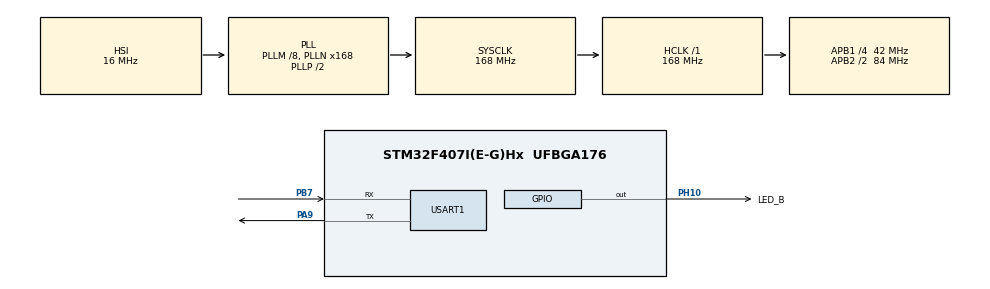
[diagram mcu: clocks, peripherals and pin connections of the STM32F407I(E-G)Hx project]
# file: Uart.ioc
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Dma.Request0=USART1_RX
Dma.Request1=USART1_TX
Dma.USART1_RX.0.Direction=DMA_PERIPH_TO_MEMORY
Dma.USART1_RX.0.FIFOMode=DMA_FIFOMODE_DISABLE
Dma.USART1_RX.0.Instance=DMA2_Stream2
Dma.USART1_RX.0.MemDataAlignment=DMA_MDATAALIGN_BYTE
Dma.USART1_RX.0.MemInc=DMA_MINC_ENABLE
Dma.USART1_RX.0.Mode=DMA_NORMAL
Dma.USART1_RX.0.PeriphDataAlignment=DMA_PDATAALIGN_BYTE
Dma.USART1_RX.0.PeriphInc=DMA_PINC_DISABLE
Dma.USART1_RX.0.Priority=DMA_PRIORITY_LOW
Dma.USART1_TX.1.Direction=DMA_MEMORY_TO_PERIPH
Dma.USART1_TX.1.FIFOMode=DMA_FIFOMODE_DISABLE
Dma.USART1_TX.1.Instance=DMA2_Stream7
Dma.USART1_TX.1.MemDataAlignment=DMA_MDATAALIGN_BYTE
Dma.USART1_TX.1.MemInc=DMA_MINC_ENABLE
Dma.USART1_TX.1.Mode=DMA_NORMAL
Dma.USART1_TX.1.PeriphDataAlignment=DMA_PDATAALIGN_BYTE
Dma.USART1_TX.1.PeriphInc=DMA_PINC_DISABLE
Dma.USART1_TX.1.Priority=DMA_PRIORITY_LOW
Mcu.Family=STM32F4
Mcu.Name=STM32F407I(E-G)Hx
Mcu.Package=UFBGA176
NVIC.DMA2_Stream2_IRQn=true\:0\:0\:false\:false\:true\:false\:true\:true
NVIC.DMA2_Stream7_IRQn=true\:0\:0\:false\:false\:true\:false\:true\:true
NVIC.PriorityGroup=NVIC_PRIORITYGROUP_4
NVIC.USART1_IRQn=true\:0\:0\:false\:false\:true\:true\:true\:true
PA9.Mode=Asynchronous
PA9.Signal=USART1_TX
PB7.Mode=Asynchronous
PB7.Signal=USART1_RX
PH0-OSC_IN.Mode=HSE-External-Oscillator
PH0-OSC_IN.Signal=RCC_OSC_IN
PH1-OSC_OUT.Mode=HSE-External-Oscillator
PH1-OSC_OUT.Signal=RCC_OSC_OUT
PH10.GPIO_Label=LED_B
PH10.GPIO_PuPd=GPIO_PULLDOWN
PH10.GPIO_Speed=GPIO_SPEED_FREQ_HIGH
PH10.PinState=GPIO_PIN_SET
PH10.Signal=GPIO_Output
ProjectManager.HeapSize=0x200
ProjectManager.StackSize=0x400
ProjectManager.TargetToolchain=MDK-ARM V5.32
RCC.48MHZClocksFreq_Value=84000000
RCC.AHBFreq_Value=168000000
RCC.APB1CLKDivider=RCC_HCLK_DIV4
RCC.APB1Freq_Value=42000000
RCC.APB1TimFreq_Value=84000000
RCC.APB2CLKDivider=RCC_HCLK_DIV2
RCC.APB2Freq_Value=84000000
RCC.APB2TimFreq_Value=168000000
RCC.CortexFreq_Value=168000000
RCC.HCLKFreq_Value=168000000
RCC.HSE_VALUE=25000000
RCC.HSI_VALUE=16000000
RCC.LSE_VALUE=32768
RCC.PLLM=8
RCC.PLLN=168
RCC.SYSCLKFreq_VALUE=168000000
RCC.SYSCLKSource=RCC_SYSCLKSOURCE_PLLCLK
RCC.VCOOutputFreq_Value=336000000
USART1.VirtualMode=VM_ASYNC
board=custom

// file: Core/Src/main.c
/* USER CODE BEGIN Header */
/**
  ******************************************************************************
  * @file           : main.c
  * @brief          : Main program body
  ******************************************************************************
  * @attention
  *
  * Copyright (c) 2023 STMicroelectronics.
  * All rights reserved.
  *
  * This software is licensed under terms that can be found in the LICENSE file
  * in the root directory of this software component.
  * If no LICENSE file comes with this software, it is provided AS-IS.
  *
  ******************************************************************************
  */
/* USER CODE END Header */
#include "main.h"
#include "dma.h"
#include "usart.h"
#include "gpio.h"

/* USER CODE BEGIN PV */
uint8_t txData[] = "Hello";
/* USER CODE END PV */

void SystemClock_Config(void);

/* USER CODE BEGIN 0 */

  uint8_t rxData[10]; // 用于接收数据的缓冲区

//  //中断回调函数
//  void HAL_UART_RxCpltCallback(UART_HandleTypeDef *huart) {
//    if (huart == &huart1) {
//      // 处理接收到的数据
//      if (rxData[0] == 'a') {
//        // 点亮LED
//        HAL_GPIO_WritePin(LED_B_GPIO_Port, LED_B_Pin, GPIO_PIN_SET);
//      } else if (rxData[0] == 'b') {
//        // 熄灭LED
//        HAL_GPIO_WritePin(LED_B_GPIO_Port, LED_B_Pin, GPIO_PIN_RESET);
//      }
//      // 启动下一次接收
//      HAL_UART_Receive_IT(&huart1, rxData, sizeof(rxData));
//    }
//  }

	 //DMA回调函数
	 void HAL_UART_RxCpltCallback(UART_HandleTypeDef *huart) {
		 if (huart == &huart1) {
				 // 处理接收到的数据
				 if (rxData[0] == 'a') {
						 // 点亮LED
						 HAL_GPIO_WritePin(LED_B_GPIO_Port, LED_B_Pin, GPIO_PIN_SET);
				 }else if (rxData[0] == 'b') {
						 // 熄灭LED
						 HAL_GPIO_WritePin(LED_B_GPIO_Port, LED_B_Pin, GPIO_PIN_RESET);
				 }
				 // 清空接收缓冲区
				 memset(rxData, 0, sizeof(rxData));
				 // 启动下一次DMA接收
				 HAL_UART_Receive_DMA(&huart1, rxData, sizeof(rxData));
		 }
	 }

/* USER CODE END 0 */

int main(void)
{
  /* USER CODE BEGIN 1 */
		//uint8_t txData[] = "ok";
  /* USER CODE END 1 */

  /* MCU Configuration--------------------------------------------------------*/

  /* Reset of all peripherals, Initializes the Flash interface and the Systick. */
  HAL_Init();

  /* Configure the system clock */
  SystemClock_Config();

  /* USER CODE BEGIN SysInit */
  MX_DMA_Init();
  /* USER CODE END SysInit */

  /* Initialize all configured peripherals */
  MX_GPIO_Init();

  MX_USART1_UART_Init();

  /* Infinite loop */
  /* USER CODE BEGIN WHILE */
  while (1)
  {

		/**************************阻塞式*************************/
    // 接收数据
//		HAL_Delay(100);
//		HAL_GPIO_WritePin(LED_B_GPIO_Port, LED_B_Pin, GPIO_PIN_SET);
//    HAL_UART_Receive(&huart1, rxData, sizeof(rxData), 1000);
//    //HAL_UART_Transmit(&huart1, txData, sizeof(txData), 1000);
//    // 检查接收到的数据
//    if (rxData[0] == 'a')
//    {
//      // 如果接收到"0"，发送"Hello"
//      uint8_t txData[] = "Hello";
//      HAL_UART_Transmit(&huart1, txData, sizeof(txData), 1000);
//    }
//    else if (rxData[0] == 'b')
//    {
//      // 如果接收到"1"，发送"World"
//      uint8_t txData[] = "World";
//      HAL_UART_Transmit(&huart1, txData, sizeof(txData), 1000);
//    }
//    // 清空接收缓冲区
//		HAL_GPIO_WritePin(LED_B_GPIO_Port, LED_B_Pin, GPIO_PIN_RESET);
//		//HAL_Delay(100);
//    memset(rxData, 0, sizeof(rxData));
//		HAL_Delay(100);

    /****************************中断式************************/
    //HAL_UART_Receive_IT(&huart1, rxData, sizeof(rxData));

    /****************************DMA****************************/
    HAL_UART_Receive_DMA(&huart1, rxData, sizeof(rxData));

    /* USER CODE END WHILE */

  }
}

void SystemClock_Config(void)
{
  RCC_OscInitTypeDef RCC_OscInitStruct = {0};
  RCC_ClkInitTypeDef RCC_ClkInitStruct = {0};

  /** Configure the main internal regulator output voltage
  */
  __HAL_RCC_PWR_CLK_ENABLE();
  __HAL_PWR_VOLTAGESCALING_CONFIG(PWR_REGULATOR_VOLTAGE_SCALE1);

  /** Initializes the RCC Oscillators according to the specified parameters
  * in the RCC_OscInitTypeDef structure.
  */
  RCC_OscInitStruct.OscillatorType = RCC_OSCILLATORTYPE_HSI;
  RCC_OscInitStruct.HSIState = RCC_HSI_ON;
  RCC_OscInitStruct.HSICalibrationValue = RCC_HSICALIBRATION_DEFAULT;
  RCC_OscInitStruct.PLL.PLLState = RCC_PLL_ON;
  RCC_OscInitStruct.PLL.PLLSource = RCC_PLLSOURCE_HSI;
  RCC_OscInitStruct.PLL.PLLM = 8;
  RCC_OscInitStruct.PLL.PLLN = 168;
  RCC_OscInitStruct.PLL.PLLP = RCC_PLLP_DIV2;
  RCC_OscInitStruct.PLL.PLLQ = 4;
  if (HAL_RCC_OscConfig(&RCC_OscInitStruct) != HAL_OK)
  {
    Error_Handler();
  }

  /** Initializes the CPU, AHB and APB buses clocks
  */
  RCC_ClkInitStruct.ClockType = RCC_CLOCKTYPE_HCLK|RCC_CLOCKTYPE_SYSCLK
                              |RCC_CLOCKTYPE_PCLK1|RCC_CLOCKTYPE_PCLK2;
  RCC_ClkInitStruct.SYSCLKSource = RCC_SYSCLKSOURCE_PLLCLK;
  RCC_ClkInitStruct.AHBCLKDivider = RCC_SYSCLK_DIV1;
  RCC_ClkInitStruct.APB1CLKDivider = RCC_HCLK_DIV4;
  RCC_ClkInitStruct.APB2CLKDivider = RCC_HCLK_DIV2;

  if (HAL_RCC_ClockConfig(&RCC_ClkInitStruct, FLASH_LATENCY_5) != HAL_OK)
  {
    Error_Handler();
  }
}

void Error_Handler(void)
{
  __disable_irq();
  while (1)
  {
  }
}
